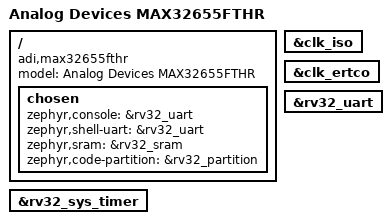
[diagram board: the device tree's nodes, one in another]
/*
 * Copyright (c) 2023-2024 Analog Devices, Inc.
 *
 * SPDX-License-Identifier: Apache-2.0
 */

/dts-v1/;

#include <adi/max32/max32655-rv32.dtsi>
#include "max32655fthr.dtsi"

/ {
	model = "Analog Devices MAX32655FTHR";
	compatible = "adi,max32655fthr";

	chosen {
		zephyr,console = &rv32_uart;
		zephyr,shell-uart = &rv32_uart;
		zephyr,sram = &rv32_sram;
		zephyr,code-partition = &rv32_partition;
	};
};

&rv32_sys_timer {
	status = "okay";
};

&clk_iso {
	status = "okay";
};

/*
 * ERTCO is required for counter RTC
 */
&clk_ertco {
	status = "okay";
};

&rv32_uart {
	status = "okay";
};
